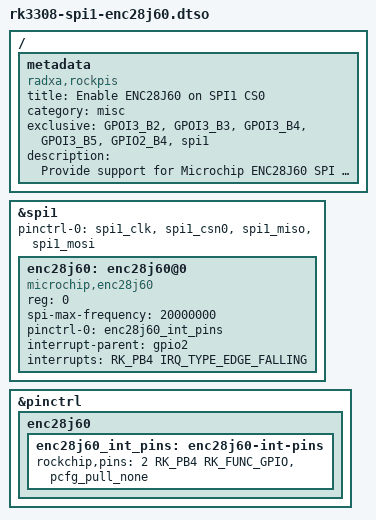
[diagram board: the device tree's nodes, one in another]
/dts-v1/;
/plugin/;

#include <dt-bindings/gpio/gpio.h>
#include <dt-bindings/pinctrl/rockchip.h>
#include <dt-bindings/interrupt-controller/irq.h>

/{
        metadata {
                title = "Enable ENC28J60 on SPI1 CS0";
                compatible = "radxa,rockpis";
                category = "misc";
                exclusive = "GPOI3_B2", "GPOI3_B3", "GPOI3_B4", "GPOI3_B5", "GPIO2_B4", "spi1";
                description = "Provide support for Microchip ENC28J60 SPI Ethernet controller on GPIO pins.
Pin definition:
MOSI=40 MISO=42 SCK=41 CS=39 INT=43";
        };
};

&spi1 {
        status = "okay";
        pinctrl-names = "default";
        pinctrl-0 = <&spi1_clk &spi1_csn0 &spi1_miso &spi1_mosi>;
        #address-cells = <1>;
        #size-cells = <0>;
        enc28j60: enc28j60@0 {
                status = "okay";
                compatible = "microchip,enc28j60";
                reg = <0>;
                spi-max-frequency = <20000000>;

                pinctrl-names = "default";
                pinctrl-0 = <&enc28j60_int_pins>;

                interrupt-parent = <&gpio2>;
                interrupts = <RK_PB4 IRQ_TYPE_EDGE_FALLING>;
        };
};

&pinctrl {
        enc28j60 {
                enc28j60_int_pins: enc28j60-int-pins {
                        rockchip,pins = <2 RK_PB4 RK_FUNC_GPIO &pcfg_pull_none>;
                };
        };
};
